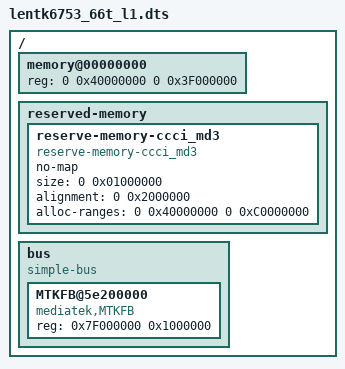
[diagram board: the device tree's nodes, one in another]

/dts-v1/;

/include/ "mt6753.dtsi"

/ {
  memory@00000000 {
		device_type = "memory";
		reg = <0 0x40000000 0 0x3F000000>;
	};
	
	reserved-memory {
		#address-cells = <2>;
		#size-cells = <2>;
		ranges;

		reserve-memory-ccci_md3 {
			compatible = "reserve-memory-ccci_md3";
			no-map;
			size = <0 0x01000000>;
			alignment = <0 0x2000000>;
			alloc-ranges = <0 0x40000000 0 0xC0000000>;
		};
	};

	bus {
		compatible = "simple-bus";
		#address-cells = <1>;
		#size-cells = <1>;
		ranges = <0 0 0 0xffffffff>;

		MTKFB@5e200000 {
			compatible = "mediatek,MTKFB";
			reg = <0x7F000000 0x1000000>;
		};

	};


};
